# STM32F215 register map
File version: 1.2
CPU: CM3 r1p1, little endian, no MPU, no FPU, 4 interrupt priority bits
Registers are 32-bit, read-write, reset 0x0 unless marked. A register's access mark holds for its fields unless they carry their own. Offsets are from the block's base; [hi:lo] are bit positions.

## Ethernet_MAC — Ethernet: media access control (MAC)
Base 0x40028000
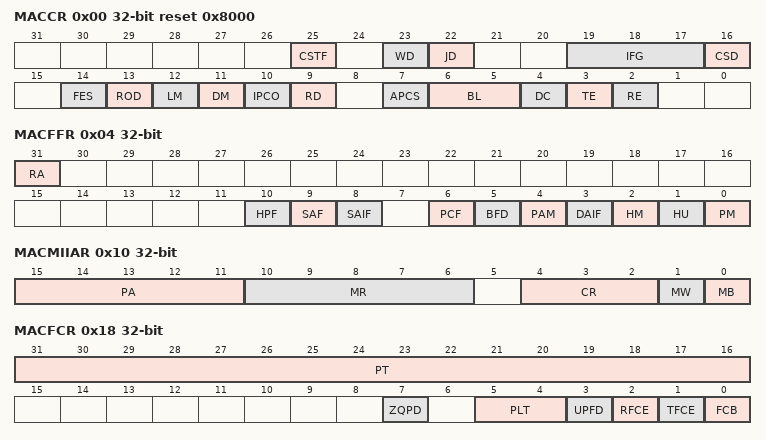
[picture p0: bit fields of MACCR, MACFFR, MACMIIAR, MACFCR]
0x00 MACCR reset 0x8000 — Ethernet MAC configuration register
  [25] CSTF, [23] WD, [22] JD, [19:17] IFG, [16] CSD, [14] FES, [13] ROD, [12] LM, [11] DM, [10] IPCO, [9] RD, [7] APCS, [6:5] BL, [4] DC, [3] TE, [2] RE
0x04 MACFFR — Ethernet MAC frame filter register
  [31] RA — Receive all
  [10] HPF — Hash or perfect filter
  [9] SAF — Source address filter
  [8] SAIF — Source address inverse filtering
  [6] PCF — Pass control frames
  [5] BFD — Broadcast frames disable
  [4] PAM — Pass all multicast
  [3] DAIF — Destination address inverse filtering
  [2] HM — Hash multicast
  [1] HU — Hash unicast
  [0] PM — Promiscuous mode
0x08 MACHTHR — Ethernet MAC hash table high register
  [31:0] HTH — Hash table high
0x0C MACHTLR — Ethernet MAC hash table low register
  [31:0] HTL — Hash table low
0x10 MACMIIAR — Ethernet MAC MII address register
  [15:11] PA — PHY address
  [10:6] MR — MII register
  [4:2] CR — Clock range
  [1] MW — MII write
  [0] MB — MII busy
0x14 MACMIIDR — Ethernet MAC MII data register
  [15:0] MD — MII data
0x18 MACFCR — Ethernet MAC flow control register
  [31:16] PT — Pause time
  [7] ZQPD — Zero-quanta pause disable
  [5:4] PLT — Pause low threshold
  [3] UPFD — Unicast pause frame detect
  [2] RFCE — Receive flow control enable
  [1] TFCE — Transmit flow control enable
  [0] FCB — Flow control busy/back pressure activate
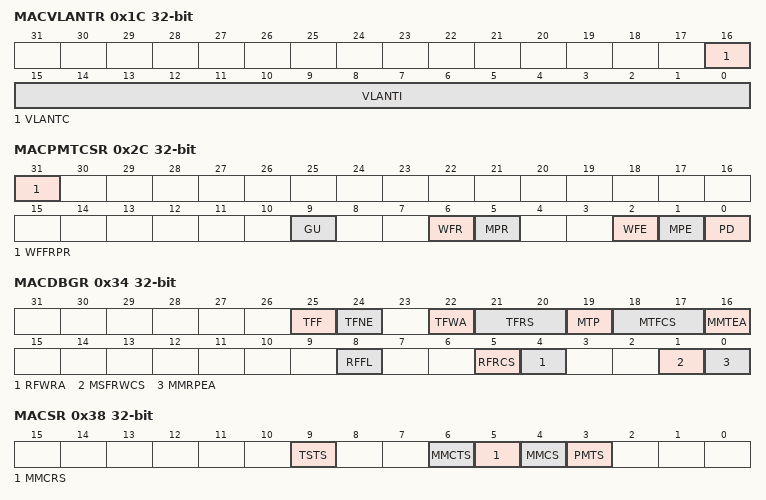
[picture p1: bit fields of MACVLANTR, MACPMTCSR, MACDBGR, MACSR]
0x1C MACVLANTR — Ethernet MAC VLAN tag register
  [16] VLANTC — 12-bit VLAN tag comparison
  [15:0] VLANTI — VLAN tag identifier
0x28 MACRWUFFR — Ethernet MAC remote wakeup frame filter register
0x2C MACPMTCSR — Ethernet MAC PMT control and status register
  [31] WFFRPR — Wakeup frame filter register pointer reset
  [9] GU — Global unicast
  [6] WFR — Wakeup frame received
  [5] MPR — Magic packet received
  [2] WFE — Wakeup frame enable
  [1] MPE — Magic Packet enable
  [0] PD — Power down
0x34 MACDBGR ro — Ethernet MAC debug register
  [25] TFF — Tx FIFO full
  [24] TFNE — Tx FIFO not empty
  [22] TFWA — Tx FIFO write active
  [21:20] TFRS — Tx FIFO read status
  [19] MTP — MAC transmitter in pause
  [18:17] MTFCS — MAC transmit frame controller status
  [16] MMTEA — MAC MII transmit engine active
  [8] RFFL — Rx FIFO fill level
  [5] RFRCS — Rx FIFO read controller status
  [4] RFWRA — Rx FIFO write controller active
  [1] MSFRWCS — MAC small FIFO read / write controllers status
  [0] MMRPEA — MAC MII receive protocol engine active
0x38 MACSR access per field — Ethernet MAC interrupt status register
  [9] TSTS rw — Time stamp trigger status
  [6] MMCTS ro — MMC transmit status
  [5] MMCRS ro — MMC receive status
  [4] MMCS ro — MMC status
  [3] PMTS ro — PMT status
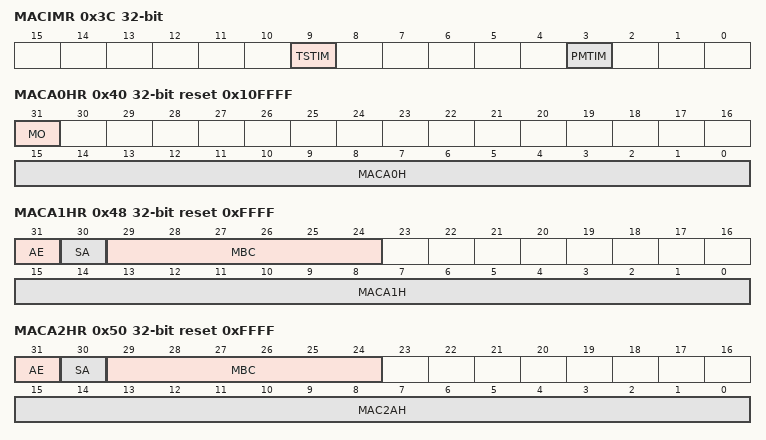
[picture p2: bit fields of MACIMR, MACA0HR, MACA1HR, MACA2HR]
0x3C MACIMR — Ethernet MAC interrupt mask register
  [9] TSTIM — Time stamp trigger interrupt mask
  [3] PMTIM — PMT interrupt mask
0x40 MACA0HR access per field reset 0x10FFFF — Ethernet MAC address 0 high register
  [31] MO ro
  [15:0] MACA0H rw — MAC address0 high
0x44 MACA0LR reset 0xFFFFFFFF — Ethernet MAC address 0 low register
  [31:0] MACA0L — MAC address0 low
0x48 MACA1HR reset 0xFFFF — Ethernet MAC address 1 high register
  [31] AE — Address enable
  [30] SA — Source address
  [29:24] MBC — Mask byte control
  [15:0] MACA1H — MAC address1 high
0x4C MACA1LR reset 0xFFFFFFFF — Ethernet MAC address1 low register
  [31:0] MACA1LR — MAC address1 low
0x50 MACA2HR reset 0xFFFF — Ethernet MAC address 2 high register
  [31] AE — Address enable
  [30] SA — Source address
  [29:24] MBC — Mask byte control
  [15:0] MAC2AH — MAC address2 high
0x54 MACA2LR reset 0xFFFFFFFF — Ethernet MAC address 2 low register
  [30:0] MACA2L — MAC address2 low
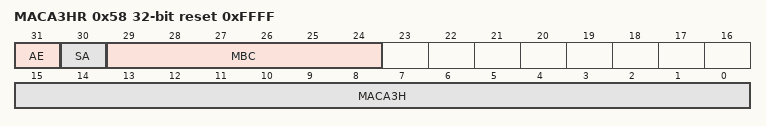
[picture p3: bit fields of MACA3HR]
0x58 MACA3HR reset 0xFFFF — Ethernet MAC address 3 high register
  [31] AE — Address enable
  [30] SA — Source address
  [29:24] MBC — Mask byte control
  [15:0] MACA3H — MAC address3 high
0x5C MACA3LR reset 0xFFFFFFFF — Ethernet MAC address 3 low register
  [31:0] MBCA3L — MAC address3 low
